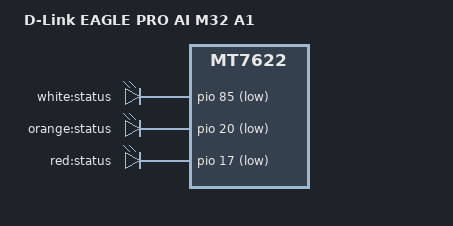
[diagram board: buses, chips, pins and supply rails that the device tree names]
// SPDX-License-Identifier: GPL-2.0-or-later OR MIT

/dts-v1/;
#include "mt7622-dlink-eagle-pro-ai-ax3200-a1.dtsi"

/ {
	model = "D-Link EAGLE PRO AI M32 A1";
	compatible = "dlink,eagle-pro-ai-m32-a1", "mediatek,mt7622";

	aliases {
		led-boot = &status_orange;
		led-failsafe = &status_red;
		led-running = &status_white;
		led-upgrade = &status_red;
	};

	leds {
		compatible = "gpio-leds";

		status_white: status_white {
			label = "white:status";
			gpios = <&pio 85 GPIO_ACTIVE_LOW>;
		};

		status_orange: status_orange {
			label = "orange:status";
			gpios = <&pio 20 GPIO_ACTIVE_LOW>;
			default-state = "on";
		};

		status_red: status_red {
			label = "red:status";
			gpios = <&pio 17 GPIO_ACTIVE_LOW>;
		};
	};
};

&switch {
	ports {
		port@2 {
			reg = <2>;
			label = "lan2";
		};

		port@3 {
			reg = <3>;
			label = "lan1";
		};
	};
};

&odm_partition {
	macaddr_odm: macaddr@83 {
		compatible = "mac-base";
		reg = <0x83 0x6>;
		#nvmem-cell-cells = <1>;
	};
};

